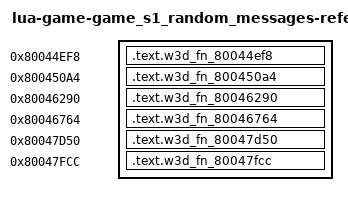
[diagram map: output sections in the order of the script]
/* Generated reference-only placements. All bodies are source-built. */
OUTPUT_FORMAT("elf32-powerpc")
OUTPUT_ARCH(powerpc)
ENTRY(w3d_fn_80044ef8)
_SDA_BASE_ = 0x804b2540;
_SDA2_BASE_ = 0x804c2540;
w3d_auto_8015ff5c = 0x8015ff5c;
w3d_fn_80043134 = 0x80043134;
w3d_fn_800fc2b0 = 0x800fc2b0;
w3d_str_80375134 = 0x80375134;
w3d_str_80375148 = 0x80375148;
w3d_str_8037515c = 0x8037515c;
w3d_str_80375170 = 0x80375170;
w3d_str_80375184 = 0x80375184;
w3d_str_80375198 = 0x80375198;
w3d_str_803751ac = 0x803751ac;
w3d_str_803751c0 = 0x803751c0;
w3d_str_803751d4 = 0x803751d4;
w3d_str_803751e8 = 0x803751e8;
w3d_str_803751fc = 0x803751fc;
w3d_str_80375210 = 0x80375210;
w3d_str_80375224 = 0x80375224;
w3d_str_80375238 = 0x80375238;
w3d_str_8037524c = 0x8037524c;
w3d_str_80375260 = 0x80375260;
w3d_str_80375274 = 0x80375274;
w3d_str_80375288 = 0x80375288;
w3d_str_8037529c = 0x8037529c;
w3d_str_8037597c = 0x8037597c;
w3d_str_80375990 = 0x80375990;
w3d_str_803759a4 = 0x803759a4;
w3d_str_803759b8 = 0x803759b8;
w3d_str_803759cc = 0x803759cc;
w3d_str_803759e0 = 0x803759e0;
w3d_str_803759f4 = 0x803759f4;
w3d_str_80375b5c = 0x80375b5c;
w3d_str_80375b70 = 0x80375b70;
w3d_str_80375b84 = 0x80375b84;
w3d_str_80375b98 = 0x80375b98;
w3d_str_80375bac = 0x80375bac;
w3d_str_80375bc0 = 0x80375bc0;
w3d_str_80375bd4 = 0x80375bd4;
w3d_str_80376344 = 0x80376344;
w3d_str_80376358 = 0x80376358;
w3d_str_8037636c = 0x8037636c;
w3d_str_80376380 = 0x80376380;
w3d_str_80376394 = 0x80376394;
w3d_str_803763a8 = 0x803763a8;
w3d_string_from_text = 0x8020bb54;
SECTIONS {
  .text.w3d_fn_80044ef8 0x80044ef8 : { *(.text.w3d_fn_80044ef8) }
  .text.w3d_fn_800450a4 0x800450a4 : { *(.text.w3d_fn_800450a4) }
  .text.w3d_fn_80046290 0x80046290 : { *(.text.w3d_fn_80046290) }
  .text.w3d_fn_80046764 0x80046764 : { *(.text.w3d_fn_80046764) }
  .text.w3d_fn_80047d50 0x80047d50 : { *(.text.w3d_fn_80047d50) }
  .text.w3d_fn_80047fcc 0x80047fcc : { *(.text.w3d_fn_80047fcc) }
  /DISCARD/ : { *(.text*) *(.rodata*) *(.data*) *(.bss*) *(.sdata*) *(.sbss*) *(.comment) }
}
